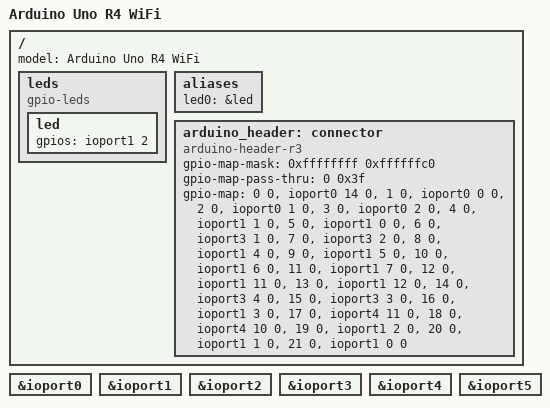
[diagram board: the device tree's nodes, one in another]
/*
 * Copyright (c) 2024 TOKITA Hiroshi <tokita.hiroshi@fujitsu.com>
 *
 * SPDX-License-Identifier: Apache-2.0
 */

/dts-v1/;
#include "arduino_uno_r4_common.dtsi"
#include "arduino_uno_r4_wifi-pinctrl.dtsi"

/ {
	model = "Arduino Uno R4 WiFi";

	leds {
		compatible = "gpio-leds";
		led: led {
			gpios = <&ioport1 2 GPIO_ACTIVE_HIGH>;
		};
	};

	aliases {
		led0 = &led;
	};

	arduino_header: connector {
		compatible = "arduino-header-r3";
		#gpio-cells = <2>;
		gpio-map-mask = <0xffffffff 0xffffffc0>;
		gpio-map-pass-thru = <0 0x3f>;
		gpio-map = <0 0 &ioport0 14 0>,   /* A0 */
			   <1 0 &ioport0 0 0>,    /* A1 */
			   <2 0 &ioport0 1 0>,    /* A2 */
			   <3 0 &ioport0 2 0>,    /* A3 */
			   <4 0 &ioport1 1 0>,    /* A4 */
			   <5 0 &ioport1 0 0>,    /* A5 */
			   <6 0 &ioport3 1 0>,    /* D0 */
			   <7 0 &ioport3 2 0>,    /* D1 */
			   <8 0 &ioport1 4 0>,    /* D2 */
			   <9 0 &ioport1 5 0>,    /* D3 */
			   <10 0 &ioport1 6 0>,   /* D4 */
			   <11 0 &ioport1 7 0>,   /* D5 */
			   <12 0 &ioport1 11 0>,  /* D6 */
			   <13 0 &ioport1 12 0>,  /* D7 */
			   <14 0 &ioport3 4 0>,   /* D8 */
			   <15 0 &ioport3 3 0>,   /* D9 */
			   <16 0 &ioport1 3 0>,   /* D10 */
			   <17 0 &ioport4 11 0>,  /* D11 */
			   <18 0 &ioport4 10 0>,  /* D12 */
			   <19 0 &ioport1 2 0>,   /* D13 */
			   <20 0 &ioport1 1 0>,   /* D14 */
			   <21 0 &ioport1 0 0>;   /* D15 */
	};
};

&ioport0 {
	/delete-property/ port-irq3-pins;  /* P004: Connect to LED Matrix */
	/delete-property/ port-irq10-pins; /* P005: Not available */
	/delete-property/ port-irq15-pins; /* P011: Connect to LED Matrix */
};

&ioport1 {
	/delete-property/ port-irq2-pins; /* P101: Conflict with P104 */
	/delete-property/ port-irq3-pins; /* P110: Connect to ESP32 */
	status = "okay";
};

&ioport2 {
	/delete-property/ port-irq0-pins; /* P206: Connect to LED Matrix */
	/delete-property/ port-irq1-pins; /* P205: Connect to LED Matrix */
	/delete-property/ port-irq2-pins; /* P213: Connect to LED Matrix */
	/delete-property/ port-irq3-pins; /* P212: Connect to LED Matrix */
};

&ioport3 {
	/delete-property/ port-irq5-pins; /* P302: Conflict with P410, choose either. */
	/delete-property/ port-irq6-pins; /* P301: Conflict with P001, choose either. */
	/delete-property/ port-irq8-pins; /* P305: Not available */
};

&ioport4 {
	/delete-property/ port-irq0-pins; /* P400: Connect to ESP32 */
	/delete-property/ port-irq4-pins; /* P411: Conflict with P111, choose either. */
	/delete-property/ port-irq6-pins; /* P409: Not connected */
	/delete-property/ port-irq7-pins; /* P408: Connect internally */
	/delete-property/ port-irq8-pins; /* P415: Not available */
	/delete-property/ port-irq9-pins; /* P414: Not available */
};

&ioport5 {
	/delete-property/ port-irq11-pins; /* P501: Connect to ESP32 */
	/delete-property/ port-irq12-pins; /* P502: Connect to ESP32 */
	/delete-property/ port-irq14-pins; /* P505: Not available */
};
